# MM32F3270 register map
File version: 3.01
CPU: CM3 r2p1, selectable endian, MPU, no FPU, 3 interrupt priority bits
Registers are 32-bit, read-write, reset 0x0 unless marked. A register's access mark holds for its fields unless they carry their own. Offsets are from the block's base; [hi:lo] are bit positions; {n}, {i} and the like mark numbered series.

## SDIO
Base 0x40018000
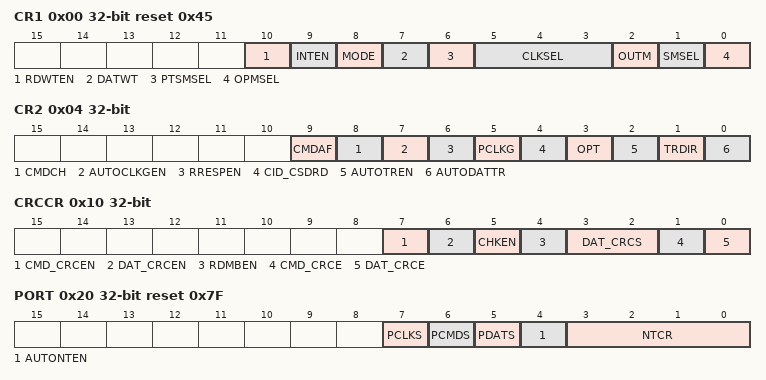
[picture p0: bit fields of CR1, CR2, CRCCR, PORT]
0x00 CR1 reset 0x45
  [10] RDWTEN — SDIO read wait enable signal
  [9] INTEN — SDIO interrupt enable signal
  [8] MODE — SDIO mode enable
  [7] DATWT — Define the bus width of SD/MMC/SDIO port DAT line
  [6] PTSMSEL — SD/MMC/SDIO port transfer speed mode selection
  [5:3] CLKSEL — SD/MMC/SDIO port CLK line speed selection
  [2] OUTM — SD/MMC/SDIO port CMD line output drive mode selection
  [1] SMSEL — Signal mode selection
  [0] OPMSEL — SD/MMC/SDIO port operation mode selection
0x04 CR2
  [9] CMDAF — SDIO cmd12/IO Abort flag
  [8] CMDCH — SDIO command character
  [7] AUTOCLKGEN — Enable auto gnerate 8 null clock after response/command or single block data
  [6] RRESPEN — Enable auto receive response after command
  [5] PCLKG — SD/MMC/SDIO port CLK line 8 null clocks generation
  [4] CID_CSDRD — CID/CSD read control bit
  [3] OPT — Response/Command selection when bit[5] is 0
  [2] AUTOTREN — Set auto 8 null/command/response transfer
  [1] TRDIR — Set data transfer direction
  [0] AUTODATTR — Set auto data transfer
0x08 BYTECNTR reset 0x200 — Data transfer byte count register
  [15:0] CNT — Data transfer byte counter
0x0C TCBLKCNTR — Data block count register
  [15:0] CNT — When multiple block transfer, transfer block count that are finished
0x10 CRCCR — CRC control register
  [7] CMD_CRCEN — SD/MMC/SDIO port CMD Line CRC circuit enable.
  [6] DAT_CRCEN — SD/MMC/SDIO port DAT Line CRC circuit enable
  [5] CHKEN — Enable auto check crc_status[2:0]
  [4] RDMBEN — Enable read multiple block data before response
  [3:2] DAT_CRCS — DAT CRC selection
  [1] CMD_CRCE — CMD CRC Error
  [0] DAT_CRCE — DAT CRC Error
0x14 CMD_CRC ro
  [6:0] VAL — CMD CRC register value
0x18 DAT_CRCL ro — CRC low data register
  [7:0] VAL — The DAT CRC low register value
0x1C DAT_CRCH ro — CRC high data register
  [7:0] VAL — The DAT CRC high register value
0x20 PORT ro reset 0x7F — MMC port register
  [7] PCLKS — SD/MMC/SDIO port CLK line signal
  [6] PCMDS — SD/MMC/SDIO port CMD line signal
  [5] PDATS — SD/MMC/SDIO port DAT line signal
  [4] AUTONTEN — Auto Ncr Timer out enable
  [3:0] NTCR — Ncr Timeout count register(SD/MMC/SDIO clock number)
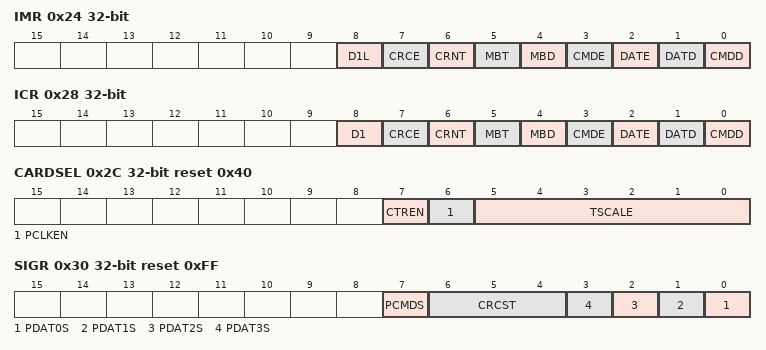
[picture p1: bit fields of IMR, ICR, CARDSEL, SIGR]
0x24 IMR — Interrupt mask register
  [8] D1L — SDIO data1 line interrupt mask
  [7] CRCE — CRC status token err interrupt mask
  [6] CRNT — Cmd and Resp Ncr Timeout interrupt mask
  [5] MBT — Multi Block Timeout interrupt mask
  [4] MBD — Multi Block done interrupt mask
  [3] CMDE — CMD CRC error interrupt mask
  [2] DATE — DAT CRC error interrupt mask
  [1] DATD — CMD done interrupt mask
  [0] CMDD — CMD done interrupt mask
0x28 ICR — Interrupt clear mask register
  [8] D1 — SDIO data1 line interrupt flag/clear bit
  [7] CRCE — CRC status error flag interrupt mask bit
  [6] CRNT — Command and response Ncr timeout interrupt mask bit
  [5] MBT — Multi-block transmission timeout interrupt mask bit
  [4] MBD — Multi-block transfer complete interrupt mask bit
  [3] CMDE — CMD CRC error interrupt mask bit
  [2] DATE — DAT CRC error interrupt mask bit
  [1] DATD — DAT complete interrupt mask bit
  [0] CMDD — CMD complete interrupt mask bit
0x2C CARDSEL reset 0x40 — card sell
  [7] CTREN — SD/MMC/SDIO controller enable
  [6] PCLKEN — SD/MMC/SDIO Time scale base(1Mhz) coefficient
  [5:0] TSCALE — SD/MMC/SDIO Time scale base(1Mhz) coefficient
0x30 SIGR ro reset 0xFF — Signal register
  [7] PCMDS — SD/MMC/SDIO port CMD Line signal
  [6:4] CRCST — CRC status[2:0] when write data CRC status token
  [n] PDAT{n}S (n=0..3) — SD/MMC/SDIO port DAT{n} Line signal
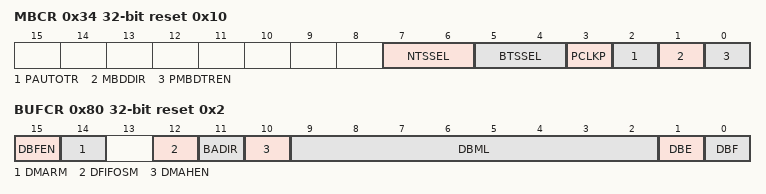
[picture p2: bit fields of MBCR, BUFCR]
0x34 MBCR reset 0x10 — Multi-block data transmission register
  [7:6] NTSSEL — SD/MMC/SDIO NAC timeout scale selection
  [5:4] BTSSEL — SD/MMC/SDIO Busy timeout scale selection
  [3] PCLKP — SD/MMC/SDIO port CLK line polarity
  [2] PAUTOTR — Set SD/MMC/SDIO port full auto cmd and multiple block data transferring
  [1] MBDDIR — Select multiple block data transfer direction
  [0] PMBDTREN — Set SD/MMC/SDIO port auto multiple block data transfer
0x38 BLKCNTR reset 0x1 — Data block count register
  [15:0] CNT — Data block number
0x3C TOCNTR reset 0x40 — Data transfer timeout count register
  [7:0] CNT — Data transfer timeout count
{0x40+4i} CMD_BUF{i} (i=0..11) — CMD buffer register {i}
  [7:0] DAT — cmd_buf byte {i}, mapped to command bit {8i+15} to bit {8i+8} bits
0x70 CMD_BUF12 — CMD buffer register 12
  [7:0] DAT — cmd_buf byte 12, mapped to the command bit 111 to bit 104 bit
0x74 CMD_BUF13 — CMD buffer register 13
  [7:0] DAT — cmd_buf byte 13, mapped to the command bit 119 to bit 112 bit
0x78 CMD_BUF14 — CMD buffer register 14
  [7:0] DAT — cmd_buf byte 14, mapped to command bit 127 to bit 120 bits
0x7C CMD_BUF15 — CMD buffer register 15
  [7:0] DAT — cmd_buf byte 15, mapped to command bit 135 to bit 128 bits
0x80 BUFCR reset 0x2 — Buffer control register
  [15] DBFEN — Data Buf flush enable
  [14] DMARM — DMA Requst mask
  [12] DFIFOSM — Data FIFO status signal mask bit
  [11] BADIR — Set buff access direction
  [10] DMAHEN — DMA hardware interface enable
  [9:2] DBML — Data buff data water mark level
  [1] DBE — Data buff empty. read-only
  [0] DBF — Data buff full
0x100 DAT_BUF — Data buffer register
  [31:0] DAT — Data buffer
